# VPAC0_KSDW_ECC_AGGR_CFG_ register map
Vendor: Texas Instruments
Peripheral module from a debugger description file (folder J7ES).
Registers are 32-bit, access not given, reset 0x0 unless marked. A register's access mark holds for its fields unless they carry their own. Offsets are as the file gives them; lines under a group give offsets from that group; [hi:lo] are bit positions; {n}, {i} and the like mark numbered series; 'fields as' and 'values as' point back to an identical list; <NAME> marks a mode.

## VPAC0_KSDW_ECC_AGGR_CFG
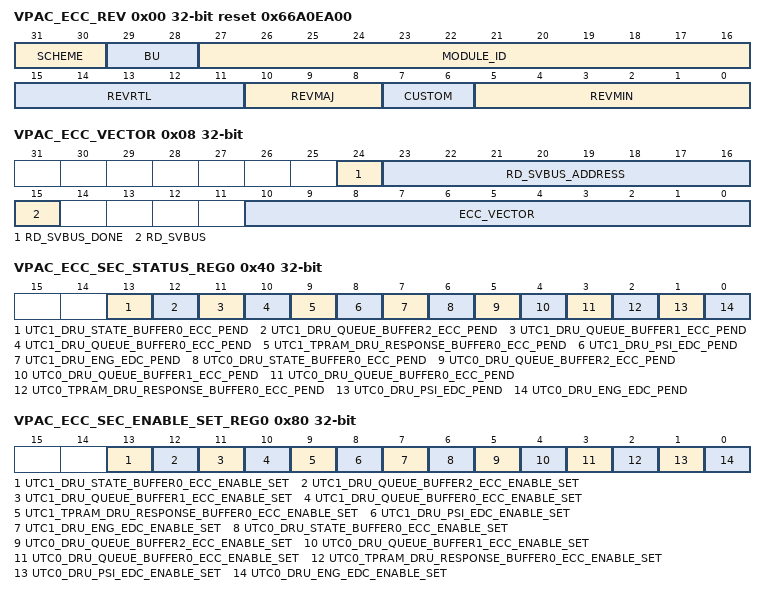
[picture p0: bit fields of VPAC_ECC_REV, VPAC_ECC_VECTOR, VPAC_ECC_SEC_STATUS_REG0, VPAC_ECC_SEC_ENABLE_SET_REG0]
0x00 VPAC_ECC_REV ro reset 0x66A0EA00 — Revision parameters
  [31:30] SCHEME
  [29:28] BU
  [27:16] MODULE_ID
  [15:11] REVRTL — RTL version
  [10:8] REVMAJ — Major version
  [7:6] CUSTOM — Custom version
  [5:0] REVMIN — Minor version
0x08 VPAC_ECC_VECTOR — ECC Register
  [24] RD_SVBUS_DONE — Status to indicate if read on serial VBUS is complete, write of any value will clear this bit. (access RW1C)
  [23:16] RD_SVBUS_ADDRESS rw — Read address
  [15] RD_SVBUS — Write 1 to trigger a read on the serial VBUS (access RW1S)
  [10:0] ECC_VECTOR rw — Value written to select the corresponding ECC RAM for control or status
0x0C VPAC_ECC_STAT ro reset 0xE — Misc Status
  [10:0] NUM_RAMS — Indicates the number of RAMS serviced by the ECC aggregator
0x10 VPAC_ECC_RESERVED_SVBUS_y rw — Reference other documents that contain the ECC RAM wrapper and EDC controller serial vbus register sets. Offset = 10h + (y * 4h); where y = 0h to 7h
  [31:0] DATA — Serial VBUS register data
0x3C VPAC_ECC_SEC_EOI_REG — EOI Register The EOI register is used to re-trigger the pulse interrupt signal to ensure that any nested interrupt events are serviced. The software interrupt handler must write to the EOI register at the end of the current interrupt processing routine, so that new events can re-trigger the pulse interrupt signal again. For level interrupt signals the EOI register is not functional and must not be used.
  [0] EOI_WR — EOI Register (access RW1S)
0x40 VPAC_ECC_SEC_STATUS_REG0 — Interrupt Status Register 0
  [13] UTC1_DRU_STATE_BUFFER0_ECC_PEND — Interrupt Pending Status for utc1_dru_state_buffer0_ecc_pend (access RW1S)
  [12] UTC1_DRU_QUEUE_BUFFER2_ECC_PEND — Interrupt Pending Status for utc1_dru_queue_buffer2_ecc_pend (access RW1S)
  [11] UTC1_DRU_QUEUE_BUFFER1_ECC_PEND — Interrupt Pending Status for utc1_dru_queue_buffer1_ecc_pend (access RW1S)
  [10] UTC1_DRU_QUEUE_BUFFER0_ECC_PEND — Interrupt Pending Status for utc1_dru_queue_buffer0_ecc_pend (access RW1S)
  [9] UTC1_TPRAM_DRU_RESPONSE_BUFFER0_ECC_PEND — Interrupt Pending Status for utc1_tpram_dru_response_buffer0_ecc_pend (access RW1S)
  [8] UTC1_DRU_PSI_EDC_PEND — Interrupt Pending Status for utc1_dru_psi_edc_pend (access RW1S)
  [7] UTC1_DRU_ENG_EDC_PEND — Interrupt Pending Status for utc1_dru_eng_edc_pend (access RW1S)
  [6] UTC0_DRU_STATE_BUFFER0_ECC_PEND — Interrupt Pending Status for utc0_dru_state_buffer0_ecc_pend (access RW1S)
  [5] UTC0_DRU_QUEUE_BUFFER2_ECC_PEND — Interrupt Pending Status for utc0_dru_queue_buffer2_ecc_pend (access RW1S)
  [4] UTC0_DRU_QUEUE_BUFFER1_ECC_PEND — Interrupt Pending Status for utc0_dru_queue_buffer1_ecc_pend (access RW1S)
  [3] UTC0_DRU_QUEUE_BUFFER0_ECC_PEND — Interrupt Pending Status for utc0_dru_queue_buffer0_ecc_pend (access RW1S)
  [2] UTC0_TPRAM_DRU_RESPONSE_BUFFER0_ECC_PEND — Interrupt Pending Status for utc0_tpram_dru_response_buffer0_ecc_pend (access RW1S)
  [1] UTC0_DRU_PSI_EDC_PEND — Interrupt Pending Status for utc0_dru_psi_edc_pend (access RW1S)
  [0] UTC0_DRU_ENG_EDC_PEND — Interrupt Pending Status for utc0_dru_eng_edc_pend (access RW1S)
0x80 VPAC_ECC_SEC_ENABLE_SET_REG0 — Interrupt Enable Set Register 0
  [13] UTC1_DRU_STATE_BUFFER0_ECC_ENABLE_SET — Interrupt Enable Set Register for utc1_dru_state_buffer0_ecc_pend (access RW1S)
  [12] UTC1_DRU_QUEUE_BUFFER2_ECC_ENABLE_SET — Interrupt Enable Set Register for utc1_dru_queue_buffer2_ecc_pend (access RW1S)
  [11] UTC1_DRU_QUEUE_BUFFER1_ECC_ENABLE_SET — Interrupt Enable Set Register for utc1_dru_queue_buffer1_ecc_pend (access RW1S)
  [10] UTC1_DRU_QUEUE_BUFFER0_ECC_ENABLE_SET — Interrupt Enable Set Register for utc1_dru_queue_buffer0_ecc_pend (access RW1S)
  [9] UTC1_TPRAM_DRU_RESPONSE_BUFFER0_ECC_ENABLE_SET — Interrupt Enable Set Register for utc1_tpram_dru_response_buffer0_ecc_pend (access RW1S)
  [8] UTC1_DRU_PSI_EDC_ENABLE_SET — Interrupt Enable Set Register for utc1_dru_psi_edc_pend (access RW1S)
  [7] UTC1_DRU_ENG_EDC_ENABLE_SET — Interrupt Enable Set Register for utc1_dru_eng_edc_pend (access RW1S)
  [6] UTC0_DRU_STATE_BUFFER0_ECC_ENABLE_SET — Interrupt Enable Set Register for utc0_dru_state_buffer0_ecc_pend (access RW1S)
  [5] UTC0_DRU_QUEUE_BUFFER2_ECC_ENABLE_SET — Interrupt Enable Set Register for utc0_dru_queue_buffer2_ecc_pend (access RW1S)
  [4] UTC0_DRU_QUEUE_BUFFER1_ECC_ENABLE_SET — Interrupt Enable Set Register for utc0_dru_queue_buffer1_ecc_pend (access RW1S)
  [3] UTC0_DRU_QUEUE_BUFFER0_ECC_ENABLE_SET — Interrupt Enable Set Register for utc0_dru_queue_buffer0_ecc_pend (access RW1S)
  [2] UTC0_TPRAM_DRU_RESPONSE_BUFFER0_ECC_ENABLE_SET — Interrupt Enable Set Register for utc0_tpram_dru_response_buffer0_ecc_pend (access RW1S)
  [1] UTC0_DRU_PSI_EDC_ENABLE_SET — Interrupt Enable Set Register for utc0_dru_psi_edc_pend (access RW1S)
  [0] UTC0_DRU_ENG_EDC_ENABLE_SET — Interrupt Enable Set Register for utc0_dru_eng_edc_pend (access RW1S)
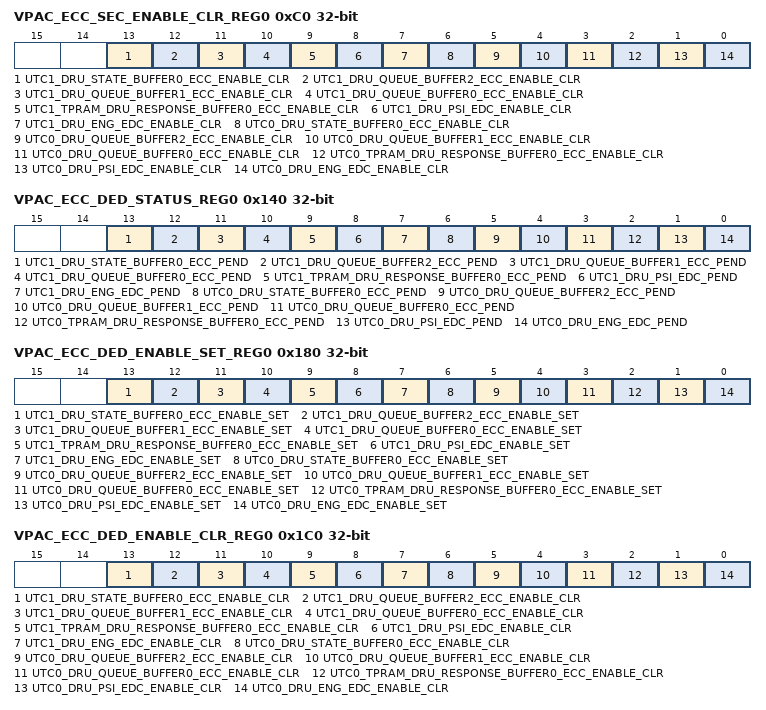
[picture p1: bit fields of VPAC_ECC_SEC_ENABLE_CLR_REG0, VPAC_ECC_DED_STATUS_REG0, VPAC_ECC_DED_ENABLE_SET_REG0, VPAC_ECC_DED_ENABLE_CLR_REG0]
0xC0 VPAC_ECC_SEC_ENABLE_CLR_REG0 — Interrupt Enable Clear Register 0
  [13] UTC1_DRU_STATE_BUFFER0_ECC_ENABLE_CLR — Interrupt Enable Clear Register for utc1_dru_state_buffer0_ecc_pend (access RW1C)
  [12] UTC1_DRU_QUEUE_BUFFER2_ECC_ENABLE_CLR — Interrupt Enable Clear Register for utc1_dru_queue_buffer2_ecc_pend (access RW1C)
  [11] UTC1_DRU_QUEUE_BUFFER1_ECC_ENABLE_CLR — Interrupt Enable Clear Register for utc1_dru_queue_buffer1_ecc_pend (access RW1C)
  [10] UTC1_DRU_QUEUE_BUFFER0_ECC_ENABLE_CLR — Interrupt Enable Clear Register for utc1_dru_queue_buffer0_ecc_pend (access RW1C)
  [9] UTC1_TPRAM_DRU_RESPONSE_BUFFER0_ECC_ENABLE_CLR — Interrupt Enable Clear Register for utc1_tpram_dru_response_buffer0_ecc_pend (access RW1C)
  [8] UTC1_DRU_PSI_EDC_ENABLE_CLR — Interrupt Enable Clear Register for utc1_dru_psi_edc_pend (access RW1C)
  [7] UTC1_DRU_ENG_EDC_ENABLE_CLR — Interrupt Enable Clear Register for utc1_dru_eng_edc_pend (access RW1C)
  [6] UTC0_DRU_STATE_BUFFER0_ECC_ENABLE_CLR — Interrupt Enable Clear Register for utc0_dru_state_buffer0_ecc_pend (access RW1C)
  [5] UTC0_DRU_QUEUE_BUFFER2_ECC_ENABLE_CLR — Interrupt Enable Clear Register for utc0_dru_queue_buffer2_ecc_pend (access RW1C)
  [4] UTC0_DRU_QUEUE_BUFFER1_ECC_ENABLE_CLR — Interrupt Enable Clear Register for utc0_dru_queue_buffer1_ecc_pend (access RW1C)
  [3] UTC0_DRU_QUEUE_BUFFER0_ECC_ENABLE_CLR — Interrupt Enable Clear Register for utc0_dru_queue_buffer0_ecc_pend (access RW1C)
  [2] UTC0_TPRAM_DRU_RESPONSE_BUFFER0_ECC_ENABLE_CLR — Interrupt Enable Clear Register for utc0_tpram_dru_response_buffer0_ecc_pend (access RW1C)
  [1] UTC0_DRU_PSI_EDC_ENABLE_CLR — Interrupt Enable Clear Register for utc0_dru_psi_edc_pend (access RW1C)
  [0] UTC0_DRU_ENG_EDC_ENABLE_CLR — Interrupt Enable Clear Register for utc0_dru_eng_edc_pend (access RW1C)
0x13C VPAC_ECC_DED_EOI_REG — EOI Register The EOI register is used to re-trigger the pulse interrupt signal to ensure that any nested interrupt events are serviced. The software interrupt handler must write to the EOI register at the end of the current interrupt processing routine, so that new events can re-trigger the pulse interrupt signal again. For level interrupt signals the EOI register is not functional and must not be used.
  [0] EOI_WR — EOI Register (access RW1S)
0x140 VPAC_ECC_DED_STATUS_REG0 — Interrupt Status Register 0
  fields as VPAC_ECC_SEC_STATUS_REG0
0x180 VPAC_ECC_DED_ENABLE_SET_REG0 — Interrupt Enable Set Register 0
  fields as VPAC_ECC_SEC_ENABLE_SET_REG0
0x1C0 VPAC_ECC_DED_ENABLE_CLR_REG0 — Interrupt Enable Clear Register 0
  fields as VPAC_ECC_SEC_ENABLE_CLR_REG0
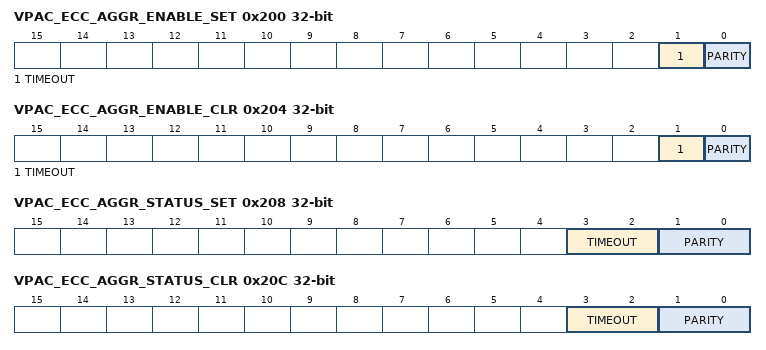
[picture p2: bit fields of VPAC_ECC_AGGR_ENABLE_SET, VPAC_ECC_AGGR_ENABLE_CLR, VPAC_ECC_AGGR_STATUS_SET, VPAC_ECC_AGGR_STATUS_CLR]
0x200 VPAC_ECC_AGGR_ENABLE_SET — AGGR interrupt enable set Register
  [1] TIMEOUT — interrupt enable set for svbus timeout errors (access RW1S)
  [0] PARITY — interrupt enable set for parity errors (access RW1S)
0x204 VPAC_ECC_AGGR_ENABLE_CLR — AGGR interrupt enable clear Register
  [1] TIMEOUT — interrupt enable clear for svbus timeout errors (access RW1C)
  [0] PARITY — interrupt enable clear for parity errors (access RW1C)
0x208 VPAC_ECC_AGGR_STATUS_SET — AGGR interrupt status set Register
  [3:2] TIMEOUT — interrupt status set for svbus timeout errors (access RWincr)
  [1:0] PARITY — interrupt status set for parity errors (access RWincr)
0x20C VPAC_ECC_AGGR_STATUS_CLR — AGGR interrupt status clear Register
  [3:2] TIMEOUT — interrupt status clear for svbus timeout errors (access RWdecr)
  [1:0] PARITY — interrupt status clear for parity errors (access RWdecr)
